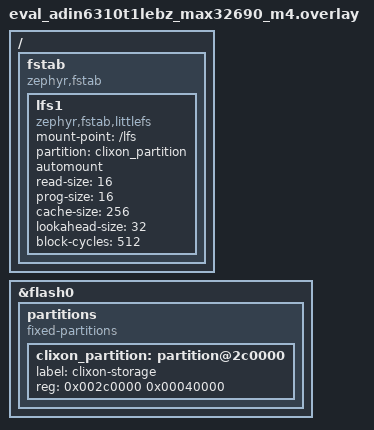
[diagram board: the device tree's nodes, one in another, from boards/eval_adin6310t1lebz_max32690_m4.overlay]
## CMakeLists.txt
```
# SPDX-License-Identifier: Apache-2.0

cmake_minimum_required(VERSION 3.20.0)

find_package(Zephyr REQUIRED HINTS $ENV{ZEPHYR_BASE})
project(clixon_sample)

target_sources(app PRIVATE src/main.c)
```

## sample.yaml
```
sample:
  name: Clixon Basic Sample
  description: Basic sample demonstrating Clixon library usage with Zephyr RTOS
common:
  tags:
    - clixon
    - netconf
    - yang
    - configuration
  platform_allow:
    - qemu_x86
    - native_sim
    - native_posix
    - eval_adin6310t1lebz/max32690/m4
  # Note: STM32 boards (e.g., nucleo_f767zi) are not supported due to
  # enum name conflict between STM32 HAL and Clixon library (SET enum)
  # See STM32_LIMITATION.md for details
  integration_platforms:
    - qemu_x86
    - native_sims
tests:
  sample.lib.clixon.basic:
    harness: console
    harness_config:
      type: multi_line
      ordered: true
      regex:
        - "Clixon Sample Application"
        - "Initializing Clixon"
        - "Clixon initialization complete"
```

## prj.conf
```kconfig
# Enable Clixon service for demonstration
# NOTE: Full Clixon library (CONFIG_CLIXON=y) not yet required
# The service provides minimal NETCONF functionality
CONFIG_CLIXON_SERVICE=y

# Enable NETCONF support
CONFIG_CLIXON_NETCONF=y

# Enable NETCONF over TLS
CONFIG_CLIXON_NETCONF_TLS=y
CONFIG_CLIXON_NETCONF_PORT=830

# TLS requires a larger mbedTLS heap for certificate parsing and crypto operations
CONFIG_MBEDTLS_HEAP_SIZE=32768

# Clixon Datastore Support
CONFIG_CLIXON_DATASTORE=y
CONFIG_CLIXON_DATASTORE_LITTLEFS=y
CONFIG_CLIXON_XMLDB_DIR="/lfs/clixon"
CONFIG_CLIXON_XMLDB_FORMAT="xml"

# POSIX support required by Clixon service
CONFIG_POSIX_API=y

# Networking stack (required by NETCONF)
CONFIG_NETWORKING=y
CONFIG_NET_IPV4=y
CONFIG_NET_IPV6=y
CONFIG_NET_TCP=y
CONFIG_NET_DHCPV4=n

# Memory configuration (increased for networking and TLS)
CONFIG_HEAP_MEM_POOL_SIZE=65536
CONFIG_MAIN_STACK_SIZE=8192
CONFIG_NET_BUF_DATA_SIZE=512

# Console and logging
CONFIG_CONSOLE=y
CONFIG_UART_CONSOLE=y
CONFIG_PRINTK=y
CONFIG_LOG=y
CONFIG_LOG_PRINTK=y
CONFIG_LOG_MODE_IMMEDIATE=y
CONFIG_SHELL=y
CONFIG_NET_SHELL=y

# mbedTLS debug logging  
CONFIG_MBEDTLS_DEBUG=n
```

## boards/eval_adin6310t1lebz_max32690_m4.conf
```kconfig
# Board-specific configuration for eval_adin6310t1lebz/max32690/m4

# Include LittleFS configuration for Clixon datastore
# The overlay file defines the flash partition

# Filesystem support
CONFIG_FILE_SYSTEM=y
CONFIG_FILE_SYSTEM_LITTLEFS=y

# Flash storage
CONFIG_FLASH=y
CONFIG_FLASH_MAP=y
CONFIG_STREAM_FLASH=y

# LittleFS settings optimized for MAX32690
CONFIG_FS_LITTLEFS_NUM_FILES=8
CONFIG_FS_LITTLEFS_NUM_DIRS=8

# Increase heap for TLS operations and filesystem (192KB)
CONFIG_HEAP_MEM_POOL_SIZE=196608

# Network configuration
CONFIG_NET_CONFIG_SETTINGS=y
CONFIG_NET_CONFIG_MY_IPV4_ADDR="192.0.2.1"
CONFIG_NET_CONFIG_MY_IPV4_NETMASK="255.255.255.0"

# Ethernet configuration
CONFIG_NET_L2_ETHERNET=y

# Increase network buffers for NETCONF
CONFIG_NET_PKT_RX_COUNT=16
CONFIG_NET_PKT_TX_COUNT=16
CONFIG_NET_BUF_RX_COUNT=32
CONFIG_NET_BUF_TX_COUNT=32

# Increase system workqueue stack for network processing
CONFIG_SYSTEM_WORKQUEUE_STACK_SIZE=4096
```

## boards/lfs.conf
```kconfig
# LittleFS configuration for Clixon datastore
# Uses internal flash partition for configuration storage

# Enable filesystem support
CONFIG_FILE_SYSTEM=y
CONFIG_FILE_SYSTEM_LITTLEFS=y

# Flash storage
CONFIG_FLASH=y
CONFIG_FLASH_MAP=y
CONFIG_STREAM_FLASH=y

# LittleFS settings (Zephyr 4.3.1 has limited Kconfig options)
# Most LittleFS parameters are configured in devicetree fstab
CONFIG_FS_LITTLEFS_NUM_FILES=8
CONFIG_FS_LITTLEFS_NUM_DIRS=8
```

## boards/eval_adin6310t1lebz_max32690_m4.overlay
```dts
/*
 * Copyright (c) 2024 Benjamin Santon ADI
 * SPDX-License-Identifier: Apache-2.0
 *
 * Clixon LittleFS storage overlay for eval_adin6310t1lebz/max32690/m4
 *
 * Allocates 256KB of internal flash for Clixon configuration storage
 * Flash layout on MAX32690 (3MB total):
 * - 0x00000000-0x002C0000: Application code (~2.75MB)
 * - 0x002C0000-0x00300000: Clixon storage (256KB) <-- This partition
 */

/ {
	fstab {
		compatible = "zephyr,fstab";
		lfs1: lfs1 {
			compatible = "zephyr,fstab,littlefs";
			mount-point = "/lfs";
			partition = <&clixon_partition>;
			automount;
			read-size = <16>;
			prog-size = <16>;
			cache-size = <256>;
			lookahead-size = <32>;
			block-cycles = <512>;
		};
	};
};

&flash0 {
	partitions {
		compatible = "fixed-partitions";
		#address-cells = <1>;
		#size-cells = <1>;

		/* Reserve last 256KB of flash for Clixon data */
		clixon_partition: partition@2c0000 {
			label = "clixon-storage";
			reg = <0x002c0000 0x00040000>; /* 256KB at 2.75MB offset */
		};
	};
};
```

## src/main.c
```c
/*
 * Copyright (c) 2024 Benjamin Santon ADI
 *
 * SPDX-License-Identifier: Apache-2.0
 */

#include <zephyr/kernel.h>
#include <zephyr/sys/printk.h>

/* Clixon headers would be included here when ready */
/* #include <clixon/clixon.h> */

#ifdef CONFIG_CLIXON_SERVICE
#include "clixon_service.h"
#endif

int main(void)
{
	printk("Clixon Sample Application\n");
	printk("=========================\n\n");

	printk("Clixon version: %s\n", "0.1.0");
	printk("This is a sample application demonstrating Clixon library integration\n");
	printk("with Zephyr RTOS.\n\n");

	/* Check if Clixon service was initialized via SYS_INIT */
	if (clixon_service_is_initialized()) {
		printk("Clixon service was initialized before main() via SYS_INIT\n");
	} else {
		printk("Clixon service is not initialized\n");
	}

	/* Example usage of Clixon features */
	printk("\nDemonstrating Clixon features:\n");
	printk("- YANG-based configuration management\n");
	printk("- NETCONF/RESTCONF interfaces\n");
	printk("- Embedded database\n");
	printk("- Transaction mechanism\n");
	printk("Clixon sample running...\n");

	return 0;
}
```
